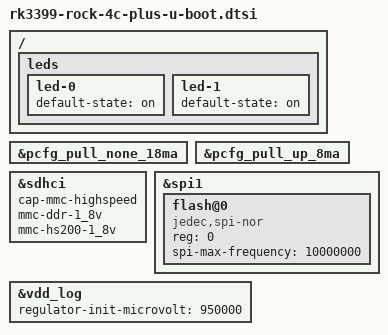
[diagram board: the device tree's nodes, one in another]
// SPDX-License-Identifier: GPL-2.0+
/*
 * Copyright (C) 2019 Jagan Teki <jagan@amarulasolutions.com>
 * Copyright (c) 2023 Radxa Limited
 */
#include "rk3399-u-boot.dtsi"
#include "rk3399-sdram-lpddr4-100.dtsi"

/ {
	leds {
		led-0 {
			default-state = "on";
		};

		led-1 {
			default-state = "on";
		};
	};
};

&pcfg_pull_none_18ma {
	bootph-pre-ram;
	bootph-some-ram;
};

&pcfg_pull_up_8ma {
	bootph-pre-ram;
	bootph-some-ram;
};

&sdhci {
	cap-mmc-highspeed;
	mmc-ddr-1_8v;
	mmc-hs200-1_8v;
};

&spi1 {
	status = "okay";

	flash@0 {
		compatible = "jedec,spi-nor";
		reg = <0>;
		bootph-pre-ram;
		bootph-some-ram;
		spi-max-frequency = <10000000>;
	};
};

&vdd_log {
	regulator-init-microvolt = <950000>;
};
